# ATSAMV71N register map
Vendor: Microchip Technology; Series: SAMV71; File version: 0
CPU: CM7 r1p1, little endian, MPU, FPU, 3 interrupt priority bits
Registers are 32-bit, read-write, reset 0x0 unless marked. A register's access mark holds for its fields unless they carry their own. Offsets are from the block's base; [hi:lo] are bit positions.

## CHIPID — Chip Identifier
Base 0x400E0940; register names take the prefix CHIPID_
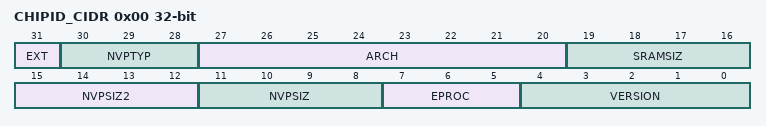
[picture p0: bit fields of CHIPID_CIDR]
0x00 CHIPID_CIDR ro — Chip ID Register
  [31] EXT — Extension Flag
  [30:28] NVPTYP — Nonvolatile Program Memory Type
    0=ROM; 1=ROMLESS (ROMless or on-chip Flash); 2=FLASH (Embedded Flash Memory); 3=ROM_FLASH (ROM and Embedded Flash Memory- NVPSIZ is ROM size- NVPSIZ2 is Flash size); 4=SRAM (SRAM emulating ROM)
  [27:20] ARCH — Architecture Identifier
    18=SAMV71
  [19:16] SRAMSIZ — Internal SRAM Size
    0=_48K (48 Kbytes); 1=_192K (192 Kbytes); 2=_384K (384 Kbytes); 3=_6K (6 Kbytes); 4=_24K (24 Kbytes); 5=_4K (4 Kbytes); 6=_80K (80 Kbytes); 7=_160K (160 Kbytes); 8=_8K (8 Kbytes); 9=_16K (16 Kbytes); 10=_32K (32 Kbytes); 11=_64K (64 Kbytes); 12=_128K (128 Kbytes); 13=_256K (256 Kbytes); 14=_96K (96 Kbytes); 15=_512K (512 Kbytes)
  [15:12] NVPSIZ2 — Second Nonvolatile Program Memory Size
    0=NONE; 1=_8K (8 Kbytes); 2=_16K (16 Kbytes); 3=_32K (32 Kbytes); 5=_64K (64 Kbytes); 7=_128K (128 Kbytes); 9=_256K (256 Kbytes); 10=_512K (512 Kbytes); 12=_1024K (1024 Kbytes); 14=_2048K (2048 Kbytes)
  [11:8] NVPSIZ — Nonvolatile Program Memory Size
    0=NONE; 1=_8K (8 Kbytes); 2=_16K (16 Kbytes); 3=_32K (32 Kbytes); 5=_64K (64 Kbytes); 7=_128K (128 Kbytes); 8=_160K (160 Kbytes); 9=_256K (256 Kbytes); 10=_512K (512 Kbytes); 12=_1024K (1024 Kbytes); 14=_2048K (2048 Kbytes)
  [7:5] EPROC — Embedded Processor
    0=SAMx7 (Cortex-M7); 1=ARM946ES; 2=ARM7TDMI; 3=CM3 (Cortex-M3); 4=ARM920T; 5=ARM926EJS; 6=CA5 (Cortex-A5); 7=CM4 (Cortex-M4)
  [4:0] VERSION — Version of the Device
0x04 CHIPID_EXID ro — Chip ID Extension Register
  [31:0] EXID — Chip ID Extension

## EFC — Embedded Flash Controller
Base 0x400E0C00; register names take the prefix EFC_
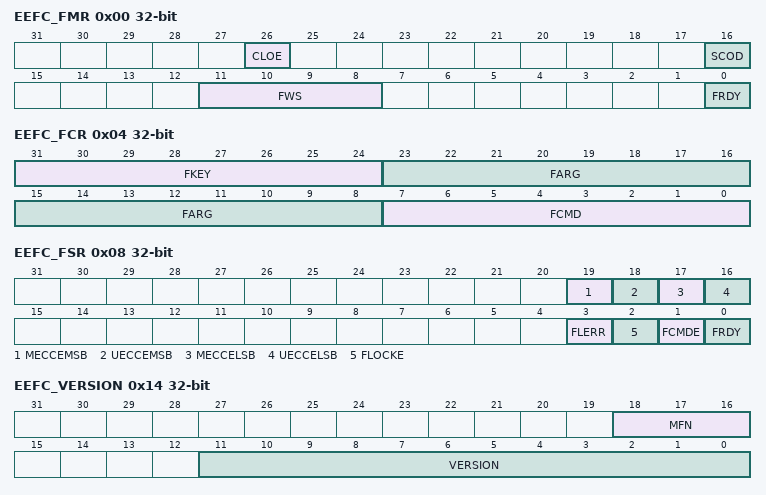
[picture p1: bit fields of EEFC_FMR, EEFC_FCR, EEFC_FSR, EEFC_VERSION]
0x00 EEFC_FMR — EEFC Flash Mode Register
  [26] CLOE — Code Loop Optimization Enable
  [16] SCOD — Sequential Code Optimization Disable
  [11:8] FWS — Flash Wait State
  [0] FRDY — Flash Ready Interrupt Enable
0x04 EEFC_FCR wo — EEFC Flash Command Register
  [31:24] FKEY — Flash Writing Protection Key
    90=PASSWD (The 0x5A value enables the command defined by the bits of the register. If the field is written with a different value, the write is not performed and no action is started.)
  [23:8] FARG — Flash Command Argument
  [7:0] FCMD — Flash Command
    0=GETD (Get Flash descriptor); 1=WP (Write page); 2=WPL (Write page and lock); 3=EWP (Erase page and write page); 4=EWPL (Erase page and write page then lock); 5=EA (Erase all); 7=EPA (Erase pages); 8=SLB (Set lock bit); 9=CLB (Clear lock bit); 10=GLB (Get lock bit); 11=SGPB (Set GPNVM bit); 12=CGPB (Clear GPNVM bit); 13=GGPB (Get GPNVM bit); 14=STUI (Start read unique identifier); 15=SPUI (Stop read unique identifier); 16=GCALB (Get CALIB bit); 17=ES (Erase sector); 18=WUS (Write user signature); 19=EUS (Erase user signature); 20=STUS (Start read user signature); 21=SPUS (Stop read user signature)
0x08 EEFC_FSR ro — EEFC Flash Status Register
  [19] MECCEMSB — Multiple ECC Error on MSB Part of the Memory Flash Data Bus (cleared on read)
  [18] UECCEMSB — Unique ECC Error on MSB Part of the Memory Flash Data Bus (cleared on read)
  [17] MECCELSB — Multiple ECC Error on LSB Part of the Memory Flash Data Bus (cleared on read)
  [16] UECCELSB — Unique ECC Error on LSB Part of the Memory Flash Data Bus (cleared on read)
  [3] FLERR — Flash Error Status (cleared when a programming operation starts)
  [2] FLOCKE — Flash Lock Error Status (cleared on read)
  [1] FCMDE — Flash Command Error Status (cleared on read or by writing EEFC_FCR)
  [0] FRDY — Flash Ready Status (cleared when Flash is busy)
0x0C EEFC_FRR ro — EEFC Flash Result Register
  [31:0] FVALUE — Flash Result Value
0x14 EEFC_VERSION ro
  [18:16] MFN — Metal Fix Number
  [11:0] VERSION — Version of the Hardware Module
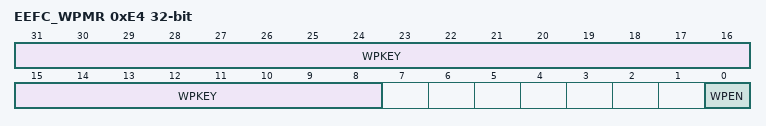
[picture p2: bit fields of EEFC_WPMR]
0xE4 EEFC_WPMR — Write Protection Mode Register
  [31:8] WPKEY — Write Protection Key
    0x454643=PASSWD (Writing any other value in this field aborts the write operation.Always reads as 0.)
  [0] WPEN — Write Protection Enable

## Notices in the file
Copyright (c) 2017 Microchip Technology Inc.
SPDX-License-Identifier: Apache-2.0
Licensed under the Apache License, Version 2.0 (the "License");
you may not use this file except in compliance with the License.
You may obtain a copy of the License at
http://www.apache.org/licenses/LICENSE-2.0
Unless required by applicable law or agreed to in writing, software
distributed under the License is distributed on an "AS IS" BASIS,
WITHOUT WARRANTIES OR CONDITIONS OF ANY KIND, either express or implied.
See the License for the specific language governing permissions and
limitations under the License.
